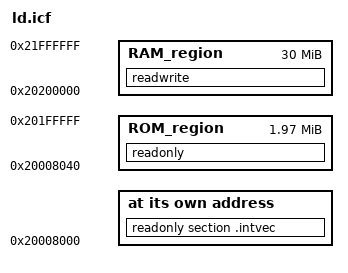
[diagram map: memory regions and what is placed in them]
/*###ICF### Section handled by ICF editor, don't touch! ****/
/*-Editor annotation file-*/
/* IcfEditorFile="$PROJ_DIR$\..\ASM9260T\edit_ASM9260T.xml" */
/*-Specials-*/
define symbol __ICFEDIT_intvec_start__ = 0x20008000;
/*-Memory Regions-*/
define symbol __ICFEDIT_region_ROM_start__ = 0x20008040;
define symbol __ICFEDIT_region_ROM_end__   = 0x201FFFFF;
define symbol __ICFEDIT_region_RAM_start__ = 0x20200000;
define symbol __ICFEDIT_region_RAM_end__   = 0x21FFFFFF;
/**** End of ICF editor section. ###ICF###*/

define exported symbol ROM_REGION_SIZE = __ICFEDIT_region_ROM_end__-__ICFEDIT_intvec_start__+1;

define memory mem with size = 4G;
define region ROM_region   = mem:[from __ICFEDIT_region_ROM_start__ to __ICFEDIT_region_ROM_end__];
define region RAM_region   = mem:[from __ICFEDIT_region_RAM_start__ to __ICFEDIT_region_RAM_end__];

initialize by copy { readwrite };
do not initialize  { section .noinit };

place at address mem:__ICFEDIT_intvec_start__ { readonly section .intvec };

place in ROM_region   { readonly };
place in RAM_region   { readwrite };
